# ATSAMA5D27 register map
Vendor: Microchip Technology Inc.; File version: 1.0
CPU: CA5 r0p1, little endian, no MPU, no FPU, 4 interrupt priority bits
Address unit: 32 bits
Registers are 32-bit, read-write, reset 0x0 unless marked. A register's access mark holds for its fields unless they carry their own. Offsets are from the block's base; [hi:lo] are bit positions; {n}, {i} and the like mark numbered series.

## XDMAC0 — Extensible DMA Controller
Base 0xF0010000
Same registers: XDMAC1 0xF0004000
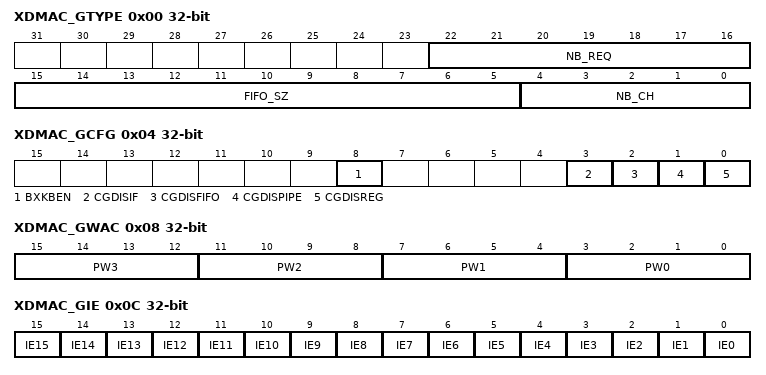
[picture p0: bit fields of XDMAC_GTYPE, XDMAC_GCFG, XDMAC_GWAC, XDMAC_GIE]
0x00 XDMAC_GTYPE ro — Global Type Register
  [22:16] NB_REQ rw — Number of Peripheral Requests Minus One
  [15:5] FIFO_SZ rw — Number of Bytes
  [4:0] NB_CH rw — Number of Channels Minus One
0x04 XDMAC_GCFG — Global Configuration Register
  [8] BXKBEN — Boundary X Kilobyte Enable
  [3] CGDISIF — Bus Interface Clock Gating Disable
  [2] CGDISFIFO — FIFO Clock Gating Disable
  [1] CGDISPIPE — Pipeline Clock Gating Disable
  [0] CGDISREG — Configuration Registers Clock Gating Disable
0x08 XDMAC_GWAC — Global Weighted Arbiter Configuration Register
  [4n+3:4n] PW{n} (n=0..3) — Pool Weight {n}
0x0C XDMAC_GIE wo — Global Interrupt Enable Register
  [n] IE{n} rw (n=0..15) — XDMAC Channel {n} Interrupt Enable Bit
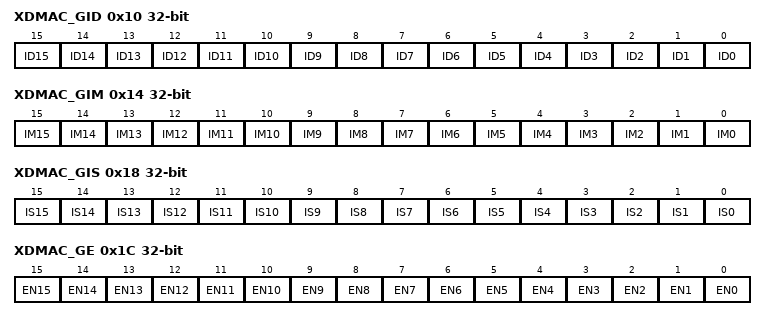
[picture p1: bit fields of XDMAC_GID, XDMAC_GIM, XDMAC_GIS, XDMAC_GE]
0x10 XDMAC_GID wo — Global Interrupt Disable Register
  [n] ID{n} rw (n=0..15) — XDMAC Channel {n} Interrupt Disable Bit
0x14 XDMAC_GIM ro — Global Interrupt Mask Register
  [n] IM{n} rw (n=0..15) — XDMAC Channel {n} Interrupt Mask Bit
0x18 XDMAC_GIS ro — Global Interrupt Status Register
  [n] IS{n} rw (n=0..15) — XDMAC Channel {n} Interrupt Status Bit
0x1C XDMAC_GE wo — Global Channel Enable Register
  [n] EN{n} rw (n=0..15) — XDMAC Channel {n} Enable Bit
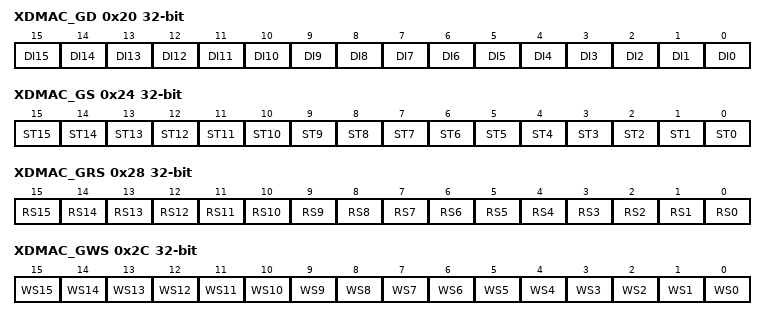
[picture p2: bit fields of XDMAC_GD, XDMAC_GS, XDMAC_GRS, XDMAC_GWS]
0x20 XDMAC_GD wo — Global Channel Disable Register
  [n] DI{n} rw (n=0..15) — XDMAC Channel {n} Disable Bit
0x24 XDMAC_GS ro — Global Channel Status Register
  [n] ST{n} rw (n=0..15) — XDMAC Channel {n} Status Bit
0x28 XDMAC_GRS — Global Channel Read Suspend Register
  [n] RS{n} (n=0..15) — XDMAC Channel {n} Read Suspend Bit
0x2C XDMAC_GWS — Global Channel Write Suspend Register
  [n] WS{n} (n=0..15) — XDMAC Channel {n} Write Suspend Bit
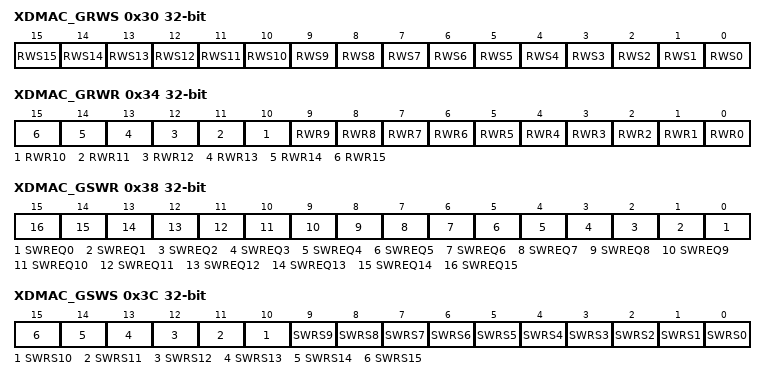
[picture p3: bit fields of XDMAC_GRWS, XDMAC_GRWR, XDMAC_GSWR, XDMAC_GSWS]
0x30 XDMAC_GRWS wo — Global Channel Read Write Suspend Register
  [n] RWS{n} rw (n=0..15) — XDMAC Channel {n} Read Write Suspend Bit
0x34 XDMAC_GRWR wo — Global Channel Read Write Resume Register
  [n] RWR{n} rw (n=0..15) — XDMAC Channel {n} Read Write Resume Bit
0x38 XDMAC_GSWR wo — Global Channel Software Request Register
  [n] SWREQ{n} rw (n=0..15) — XDMAC Channel {n} Software Request Bit
0x3C XDMAC_GSWS ro — Global Channel Software Request Status Register
  [n] SWRS{n} rw (n=0..15) — XDMAC Channel {n} Software Request Status Bit
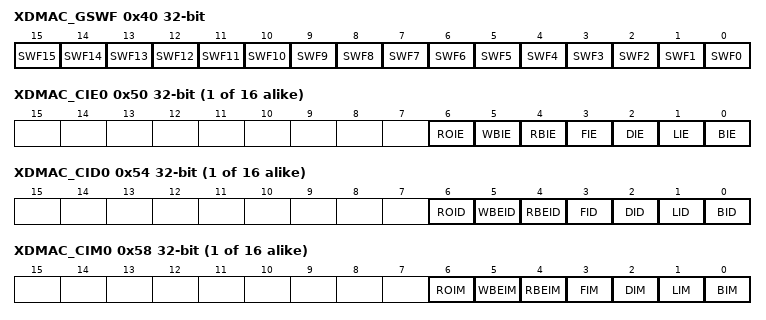
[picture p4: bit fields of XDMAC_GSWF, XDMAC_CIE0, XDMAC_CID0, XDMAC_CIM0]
0x40 XDMAC_GSWF wo — Global Channel Software Flush Request Register
  [n] SWF{n} rw (n=0..15) — XDMAC Channel {n} Software Flush Request Bit
{0x50+0x40*i} XDMAC_CIE{i} wo (i=0..15) — Channel {i} Interrupt Enable register
  [6] ROIE rw — Request Overflow Error Interrupt Enable
  [5] WBIE rw — Write Bus Error Interrupt Enable
  [4] RBIE rw — Read Bus Error Interrupt Enable
  [3] FIE rw — End of Flush Interrupt Enable
  [2] DIE rw — End of Disable Interrupt Enable
  [1] LIE rw — End of Linked List Interrupt Enable
  [0] BIE rw — End of Block Interrupt Enable
{0x54+0x40*i} XDMAC_CID{i} wo (i=0..15) — Channel {i} Interrupt Disable register
  [6] ROID rw — Request Overflow Error Interrupt Disable
  [5] WBEID rw — Write Bus Error Interrupt Disable
  [4] RBEID rw — Read Bus Error Interrupt Disable
  [3] FID rw — End of Flush Interrupt Disable
  [2] DID rw — End of Disable Interrupt Disable
  [1] LID rw — End of Linked List Interrupt Disable
  [0] BID rw — End of Block Interrupt Disable
{0x58+0x40*i} XDMAC_CIM{i} wo (i=0..15) — Channel {i} Interrupt Mask register
  [6] ROIM rw — Request Overflow Error Interrupt Mask
  [5] WBEIM rw — Write Bus Error Interrupt Mask
  [4] RBEIM rw — Read Bus Error Interrupt Mask
  [3] FIM rw — End of Flush Interrupt Mask
  [2] DIM rw — End of Disable Interrupt Mask
  [1] LIM rw — End of Linked List Interrupt Mask
  [0] BIM rw — End of Block Interrupt Mask
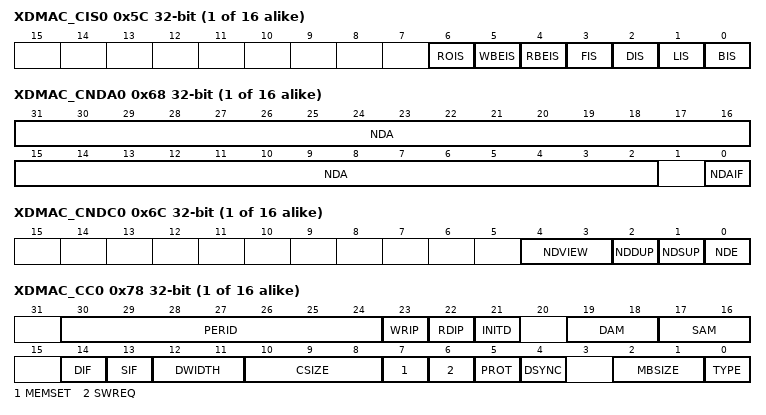
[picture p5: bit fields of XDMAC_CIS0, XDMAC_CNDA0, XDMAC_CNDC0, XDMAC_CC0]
{0x5C+0x40*i} XDMAC_CIS{i} ro (i=0..15) — Channel {i} Interrupt Status register
  [6] ROIS rw — Request Overflow Error Interrupt Status
  [5] WBEIS rw — Write Bus Error Interrupt Status
  [4] RBEIS rw — Read Bus Error Interrupt Status
  [3] FIS rw — End of Flush Interrupt Status
  [2] DIS rw — End of Disable Interrupt Status
  [1] LIS rw — End of Linked List Interrupt Status
  [0] BIS rw — Channel 0 Write Suspend Bit
{0x60+0x40*i} XDMAC_CSA{i} (i=0..15) — Channel {i} Source Address register
  [31:0] SA — Channel {i} Source Address
{0x64+0x40*i} XDMAC_CDA{i} (i=0..15) — Channel {i} Destination Address register
  [31:0] DA — Channel {i} Destination Address
{0x68+0x40*i} XDMAC_CNDA{i} (i=0..15) — Channel {i} Next Descriptor Address register
  [31:2] NDA — Channel {i} Next Descriptor Address
  [0] NDAIF — Channel {i} Next Descriptor Interface
{0x6C+0x40*i} XDMAC_CNDC{i} (i=0..15) — Channel {i} Next Descriptor Control register
  [4:3] NDVIEW — Channel {i} Next Descriptor View
  [2] NDDUP — Channel {i} Next Descriptor Destination Update
  [1] NDSUP — Channel {i} Next Descriptor Source Update
  [0] NDE — Channel {i} Next Descriptor Enable
{0x70+0x40*i} XDMAC_CUBC{i} (i=0..15) — Channel {i} Microblock Control register
  [23:0] UBLEN — Channel {i} Microblock Length
{0x74+0x40*i} XDMAC_CBC{i} (i=0..15) — Channel {i} Block Control register
  [11:0] BLEN — Channel {i} Block Length
{0x78+0x40*i} XDMAC_CC{i} (i=0..15) — Channel {i} Configuration register
  [30:24] PERID — Channel {i} Peripheral Hardware Request Line Identifier
  [23] WRIP — Write in Progress
  [22] RDIP — Read in Progress
  [21] INITD — Channel Initialization Done
  [19:18] DAM — Channel {i} Destination Addressing Mode
  [17:16] SAM — Channel {i} Source Addressing Mode
  [14] DIF — Channel {i} Destination Interface Identifier
  [13] SIF — Channel {i} Source Interface Identifier
  [12:11] DWIDTH — Channel {i} Data Width
  [10:8] CSIZE — Channel {i} Chunk Size
  [7] MEMSET — Channel {i} Fill Block of Memory
  [6] SWREQ — Channel {i} Software Request Trigger
  [5] PROT — Channel {i} Protection
  [4] DSYNC — Channel {i} Synchronization
  [2:1] MBSIZE — Channel {i} Memory Burst Size
  [0] TYPE — Channel {i} Transfer Type
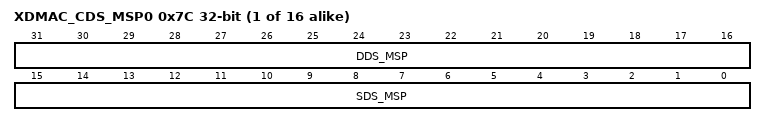
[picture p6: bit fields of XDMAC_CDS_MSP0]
{0x7C+0x40*i} XDMAC_CDS_MSP{i} (i=0..15) — Channel {i} Data Stride Memory Set Pattern register
  [31:16] DDS_MSP — Channel {i} Destination Data Stride or Memory Set Pattern
  [15:0] SDS_MSP — Channel {i} Source Data Stride or Memory Set Pattern
{0x80+0x40*i} XDMAC_CSUS{i} (i=0..15) — Channel {i} Source Microblock Stride register
  [23:0] SUBS — Channel {i} Source Microblock Stride
{0x84+0x40*i} XDMAC_CDUS{i} (i=0..15) — Channel {i} Destination Microblock Stride register
  [23:0] DUBS — Channel {i} Destination Microblock Stride
